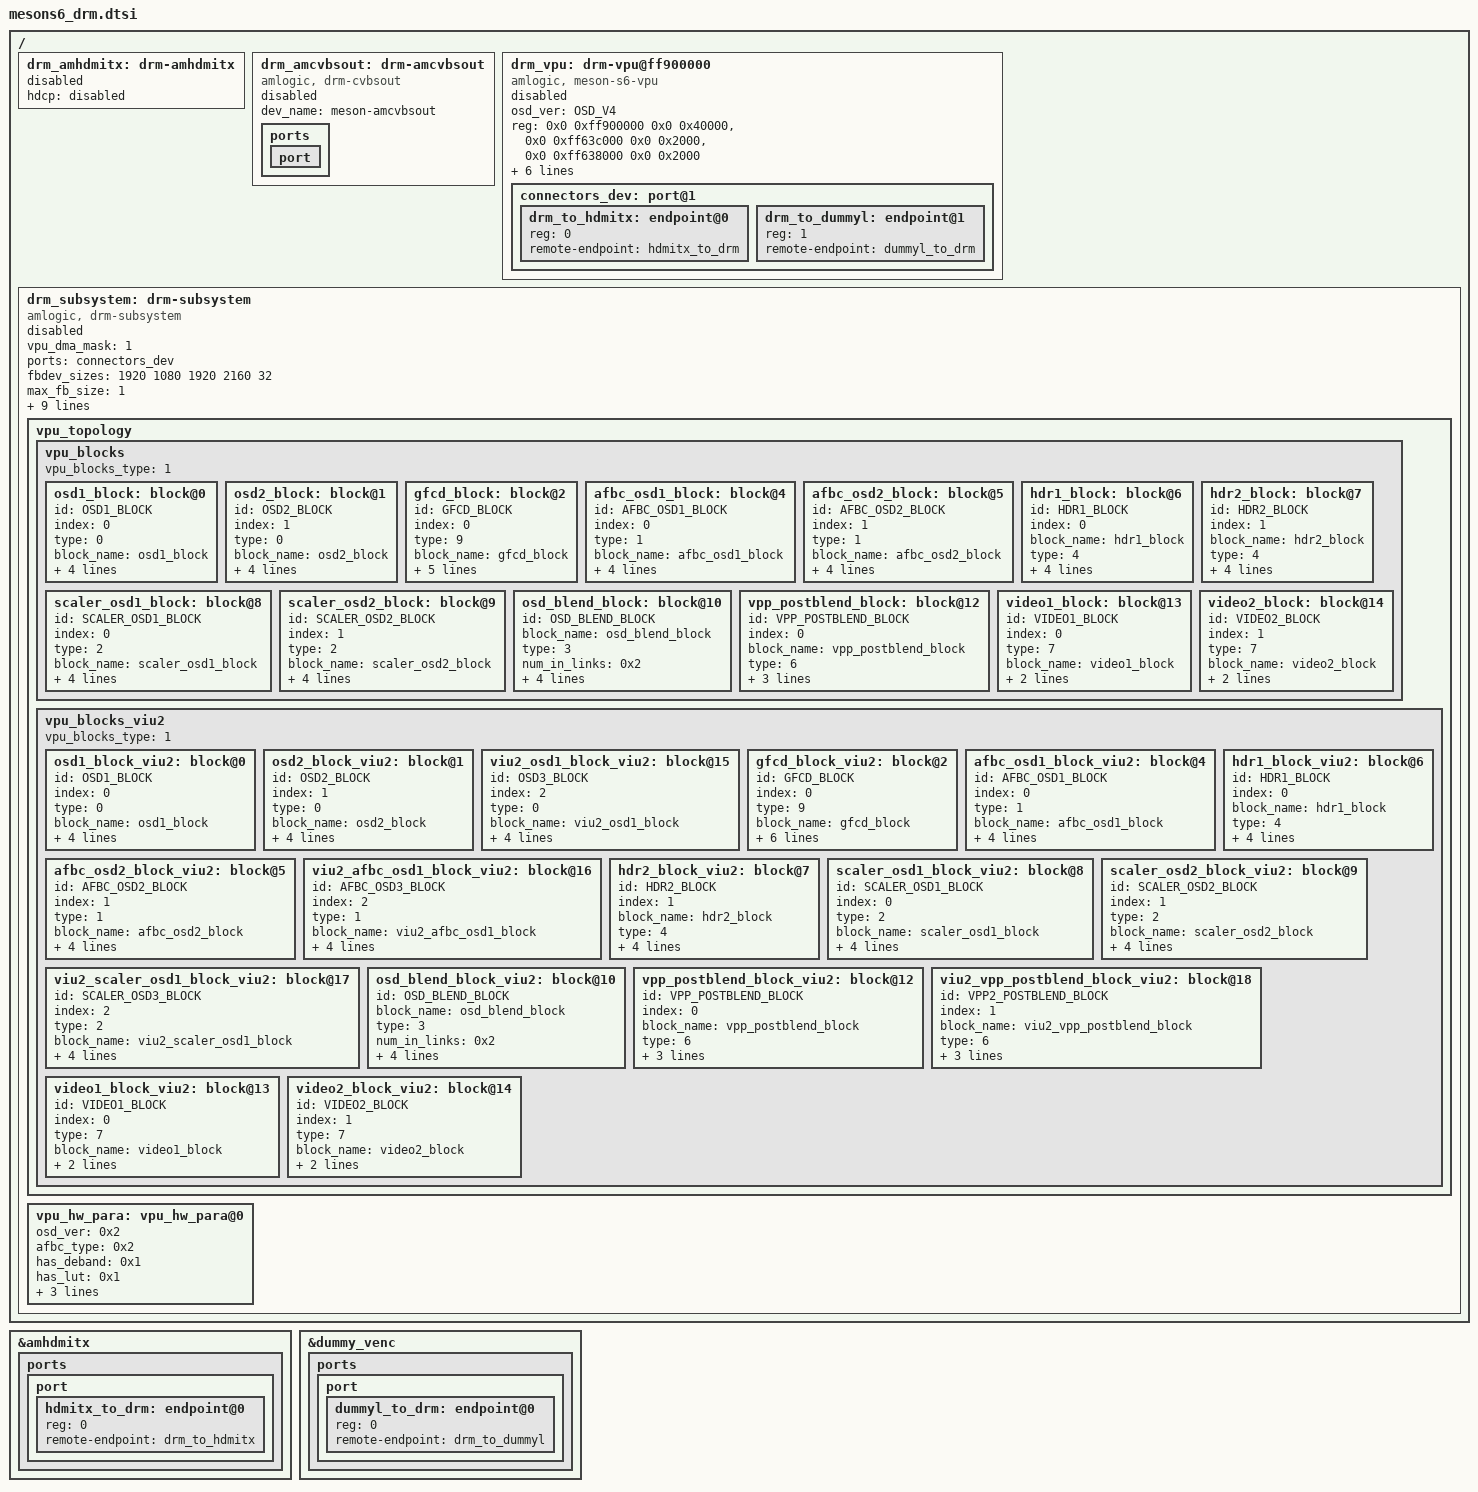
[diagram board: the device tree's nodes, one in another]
// SPDX-License-Identifier: (GPL-2.0+ OR MIT)
/*
 * Copyright (c) 2019 Amlogic, Inc. All rights reserved.
 */

#include <dt-bindings/display/meson-drm-ids.h>
#include "meson-s6.dtsi"

/ {
	drm_amhdmitx: drm-amhdmitx {
		status = "disabled";
		hdcp = "disabled";
	};

	drm_amcvbsout: drm-amcvbsout {
		status = "disabled";
		compatible = "amlogic, drm-cvbsout";
		dev_name = "meson-amcvbsout";
		ports {
			port {
				#address-cells = <1>;
				#size-cells = <0>;
			};
		};
	};

	drm_vpu: drm-vpu@ff900000  {
		status = "disabled";
		compatible = "amlogic, meson-s6-vpu";
		osd_ver = /bits/ 8 <OSD_V4>;
		reg = <0x0 0xff900000 0x0 0x40000>,
			  <0x0 0xff63c000 0x0 0x2000>,
			  <0x0 0xff638000 0x0 0x2000>;
		reg-names = "base", "hhi", "dmc";
		interrupts = <GIC_SPI 197 IRQ_TYPE_LEVEL_HIGH>,
				<GIC_SPI 194 IRQ_TYPE_LEVEL_HIGH>;
		interrupt-names = "viu-vsync", "viu2-vsync";
		dma-coherent;
		clocks = <&clkc CLKID_VPU_CLKC>;
		clock-names = "vpu_clkc";
		assigned-clocks = <&clkc CLKID_VPU_CLKC>;
		assigned-clock-rates = <200000000>;
		/*EXTERNAL port for driver outside of drm.*/
		connectors_dev: port@1 {
			#address-cells = <1>;
			#size-cells = <0>;
			drm_to_hdmitx: endpoint@0 {
				reg = <0>;
				remote-endpoint = <&hdmitx_to_drm>;
			};
			drm_to_dummyl: endpoint@1 {
				reg = <1>;
				remote-endpoint = <&dummyl_to_drm>;
			};
		};
	};

	drm_subsystem: drm-subsystem {
		status = "disabled";
		compatible = "amlogic, drm-subsystem";
		vpu_dma_mask = <1>; /* 0: <= 4G, 1: > 4G */
		ports = <&connectors_dev>;
		fbdev_sizes = <1920 1080 1920 2160 32>;
		max_fb_size = <1>; /** 0:1080p fb 1:4k fb */
		memory-region = <&logo_reserved>;
		primary_plane_index = <0>; /* primary plane index for crtcs */
		crtc_masks = <1 0 0>; /*for encoder: 0:hdmi 1:lcd 2:cvbs*/
		crtcmask_of_osd = <0 0 1>; /* indicate the crtc mask of osd plane */
		gamma_ctl = <0>; /*0:skip gamma init 1:gamma init*/
		pxp_mode = <0>;
		gfcd_enable = /bits/ 8  <1>;
		afbc_aligned_size = <1>; /*0:fbdev alloc non-afbc memory 1:fbdev alloc afbc memory*/
		vpu_block_select = <&vpu_blocks>;

		vpu_topology: vpu_topology {
			vpu_blocks: vpu_blocks {
				/*0:scaler1 after osdblend, 1:scaler1 before osdblend*/
				vpu_blocks_type = <1>;
				osd1_block: block@0 {
					id = /bits/ 8 <OSD1_BLOCK>;
					index = /bits/ 8  <0>;
					type = /bits/ 8  <0>;
					block_name = "osd1_block";
					num_in_links = /bits/ 8  <0x0>;
					num_out_links = /bits/ 8  <0x1>;
					out_links = <0 &gfcd_block>;
					capability = /bits/ 64 <0x80000C9F>;
				};
				osd2_block: block@1 {
					id = /bits/ 8  <OSD2_BLOCK>;
					index = /bits/ 8  <1>;
					type = /bits/ 8  <0>;
					block_name = "osd2_block";
					num_in_links = /bits/ 8  <0x0>;
					num_out_links = /bits/ 8  <0x1>;
					out_links = <1 &gfcd_block>;
					capability = /bits/ 64 <0x80000C9F>;
				};
				gfcd_block: block@2 {
					id = /bits/ 8  <GFCD_BLOCK>;
					index = /bits/ 8  <0>;
					type = /bits/ 8  <9>;
					block_name = "gfcd_block";
					num_in_links = /bits/ 8  <0x2>;
					in_links = <0 &osd1_block>,
						<0 &osd2_block>;
					num_out_links = /bits/ 8  <0x2>;
					out_links = <0 &afbc_osd1_block>,
						<0 &afbc_osd2_block>;
				};
				afbc_osd1_block: block@4 {
					id = /bits/ 8  <AFBC_OSD1_BLOCK>;
					index = /bits/ 8  <0>;
					type = /bits/ 8  <1>;
					block_name = "afbc_osd1_block";
					num_in_links = /bits/ 8  <0x1>;
					in_links = <0 &gfcd_block>;
					num_out_links = /bits/ 8  <0x1>;
					out_links = <0 &hdr1_block>;
				};
				afbc_osd2_block: block@5 {
					id = /bits/ 8  <AFBC_OSD2_BLOCK>;
					index = /bits/ 8  <1>;
					type = /bits/ 8  <1>;
					block_name = "afbc_osd2_block";
					num_in_links = /bits/ 8  <0x1>;
					in_links = <1 &gfcd_block>;
					num_out_links = /bits/ 8  <0x1>;
					out_links = <0 &hdr2_block>;
				};
				hdr1_block: block@6 {
					id = /bits/ 8  <HDR1_BLOCK>;
					index = /bits/ 8  <0>;
					block_name = "hdr1_block";
					type = /bits/ 8  <4>;
					num_in_links = /bits/ 8  <0x1>;
					in_links = <0 &afbc_osd1_block>;
					num_out_links = /bits/ 8  <0x1>;
					out_links = <0 &scaler_osd1_block>;
				};
				hdr2_block: block@7 {
					id = /bits/ 8  <HDR2_BLOCK>;
					index = /bits/ 8  <1>;
					block_name = "hdr2_block";
					type = /bits/ 8  <4>;
					num_in_links = /bits/ 8  <0x1>;
					in_links = <0 &afbc_osd2_block>;
					num_out_links = /bits/ 8  <0x1>;
					out_links = <0 &scaler_osd2_block>;
				};
				scaler_osd1_block: block@8 {
					id = /bits/ 8  <SCALER_OSD1_BLOCK>;
					index = /bits/ 8  <0>;
					type = /bits/ 8  <2>;
					block_name = "scaler_osd1_block";
					num_in_links = /bits/ 8  <0x1>;
					in_links = <0 &hdr1_block>;
					num_out_links = /bits/ 8  <0x1>;
					out_links = <0 &osd_blend_block>;
				};
				scaler_osd2_block: block@9 {
					id = /bits/ 8  <SCALER_OSD2_BLOCK>;
					index = /bits/ 8  <1>;
					type = /bits/ 8  <2>;
					block_name = "scaler_osd2_block";
					num_in_links = /bits/ 8  <0x1>;
					in_links = <0 &hdr2_block>;
					num_out_links = /bits/ 8  <0x1>;
					out_links = <2 &osd_blend_block>;
				};
				osd_blend_block: block@10 {
					id = /bits/ 8  <OSD_BLEND_BLOCK>;
					block_name = "osd_blend_block";
					type = /bits/ 8  <3>;
					num_in_links = /bits/ 8  <0x2>;
					in_links = <0 &scaler_osd1_block>,
						<0 &scaler_osd2_block>;
					num_out_links = /bits/ 8  <0x1>;
					out_links = <0 &vpp_postblend_block>;
				};
				vpp_postblend_block: block@12 {
					id = /bits/ 8  <VPP_POSTBLEND_BLOCK>;
					index = /bits/ 8  <0>;
					block_name = "vpp_postblend_block";
					type = /bits/ 8  <6>;
					num_in_links = /bits/ 8  <0x1>;
					in_links = <0 &osd_blend_block>;
					num_out_links = <0x0>;
				};
				video1_block: block@13 {
					id = /bits/ 8 <VIDEO1_BLOCK>;
					index = /bits/ 8  <0>;
					type = /bits/ 8  <7>;
					block_name = "video1_block";
					num_in_links = /bits/ 8  <0x0>;
					num_out_links = /bits/ 8  <0x0>;
				};
				video2_block: block@14 {
					id = /bits/ 8 <VIDEO2_BLOCK>;
					index = /bits/ 8  <1>;
					type = /bits/ 8  <7>;
					block_name = "video2_block";
					num_in_links = /bits/ 8  <0x0>;
					num_out_links = /bits/ 8  <0x0>;
				};
			};
			vpu_blocks_viu2: vpu_blocks_viu2 {
				/*0:scaler1 after osdblend, 1:scaler1 before osdblend*/
				vpu_blocks_type = <1>;
				osd1_block_viu2: block@0 {
					id = /bits/ 8 <OSD1_BLOCK>;
					index = /bits/ 8  <0>;
					type = /bits/ 8  <0>;
					block_name = "osd1_block";
					num_in_links = /bits/ 8  <0x0>;
					num_out_links = /bits/ 8  <0x1>;
					out_links = <0 &gfcd_block_viu2>;
					capability = /bits/ 64 <0x80000C9F>;
				};
				osd2_block_viu2: block@1 {
					id = /bits/ 8  <OSD2_BLOCK>;
					index = /bits/ 8  <1>;
					type = /bits/ 8  <0>;
					block_name = "osd2_block";
					num_in_links = /bits/ 8  <0x0>;
					num_out_links = /bits/ 8  <0x1>;
					out_links = <1 &gfcd_block_viu2>;
					capability = /bits/ 64 <0x80000C9F>;
				};
				viu2_osd1_block_viu2: block@15 {
					id = /bits/ 8  <OSD3_BLOCK>;
					index = /bits/ 8  <2>;
					type = /bits/ 8  <0>;
					block_name = "viu2_osd1_block";
					num_in_links = /bits/ 8  <0x0>;
					num_out_links = /bits/ 8  <0x1>;
					out_links = <0 &viu2_afbc_osd1_block_viu2>;
					capability = /bits/ 64 <0x80000003>;
				};
				gfcd_block_viu2: block@2 {
					id = /bits/ 8  <GFCD_BLOCK>;
					index = /bits/ 8  <0>;
					type = /bits/ 8  <9>;
					block_name = "gfcd_block";
					num_in_links = /bits/ 8  <0x2>;
					in_links = <0 &osd1_block_viu2>,
						<0 &osd2_block_viu2>;
					num_out_links = /bits/ 8  <0x2>;
					out_links = <0 &afbc_osd1_block_viu2>,
						<0 &afbc_osd2_block_viu2>;
				};
				afbc_osd1_block_viu2: block@4 {
					id = /bits/ 8  <AFBC_OSD1_BLOCK>;
					index = /bits/ 8  <0>;
					type = /bits/ 8  <1>;
					block_name = "afbc_osd1_block";
					num_in_links = /bits/ 8  <0x1>;
					in_links = <0 &gfcd_block_viu2>;
					num_out_links = /bits/ 8  <0x1>;
					out_links = <0 &hdr1_block_viu2>;
				};
				afbc_osd2_block_viu2: block@5 {
					id = /bits/ 8  <AFBC_OSD2_BLOCK>;
					index = /bits/ 8  <1>;
					type = /bits/ 8  <1>;
					block_name = "afbc_osd2_block";
					num_in_links = /bits/ 8  <0x1>;
					in_links = <1 &gfcd_block_viu2>;
					num_out_links = /bits/ 8  <0x1>;
					out_links = <0 &hdr2_block_viu2>;
				};
				viu2_afbc_osd1_block_viu2: block@16 {
					id = /bits/ 8  <AFBC_OSD3_BLOCK>;
					index = /bits/ 8  <2>;
					type = /bits/ 8  <1>;
					block_name = "viu2_afbc_osd1_block";
					num_in_links = /bits/ 8  <0x1>;
					in_links = <0 &viu2_osd1_block_viu2>;
					num_out_links = /bits/ 8  <0x1>;
					out_links = <0 &viu2_scaler_osd1_block_viu2>;
				};
				hdr1_block_viu2: block@6 {
					id = /bits/ 8  <HDR1_BLOCK>;
					index = /bits/ 8  <0>;
					block_name = "hdr1_block";
					type = /bits/ 8  <4>;
					num_in_links = /bits/ 8  <0x1>;
					in_links = <0 &afbc_osd1_block_viu2>;
					num_out_links = /bits/ 8  <0x1>;
					out_links = <0 &scaler_osd1_block_viu2>;
				};
				hdr2_block_viu2: block@7 {
					id = /bits/ 8  <HDR2_BLOCK>;
					index = /bits/ 8  <1>;
					block_name = "hdr2_block";
					type = /bits/ 8  <4>;
					num_in_links = /bits/ 8  <0x1>;
					in_links = <0 &afbc_osd2_block_viu2>;
					num_out_links = /bits/ 8  <0x1>;
					out_links = <0 &scaler_osd2_block_viu2>;
				};
				scaler_osd1_block_viu2: block@8 {
					id = /bits/ 8  <SCALER_OSD1_BLOCK>;
					index = /bits/ 8  <0>;
					type = /bits/ 8  <2>;
					block_name = "scaler_osd1_block";
					num_in_links = /bits/ 8  <0x1>;
					in_links = <0 &hdr1_block_viu2>;
					num_out_links = /bits/ 8  <0x1>;
					out_links = <0 &osd_blend_block_viu2>;
				};
				scaler_osd2_block_viu2: block@9 {
					id = /bits/ 8  <SCALER_OSD2_BLOCK>;
					index = /bits/ 8  <1>;
					type = /bits/ 8  <2>;
					block_name = "scaler_osd2_block";
					num_in_links = /bits/ 8  <0x1>;
					in_links = <0 &hdr2_block_viu2>;
					num_out_links = /bits/ 8  <0x1>;
					out_links = <2 &osd_blend_block_viu2>;
				};
				viu2_scaler_osd1_block_viu2: block@17 {
					id = /bits/ 8  <SCALER_OSD3_BLOCK>;
					index = /bits/ 8  <2>;
					type = /bits/ 8  <2>;
					block_name = "viu2_scaler_osd1_block";
					num_in_links = /bits/ 8  <0x1>;
					in_links = <0 &viu2_afbc_osd1_block_viu2>;
					num_out_links = /bits/ 8  <0x1>;
					out_links = <0 &viu2_vpp_postblend_block_viu2>;
				};
				osd_blend_block_viu2: block@10 {
					id = /bits/ 8  <OSD_BLEND_BLOCK>;
					block_name = "osd_blend_block";
					type = /bits/ 8  <3>;
					num_in_links = /bits/ 8  <0x2>;
					in_links = <0 &scaler_osd1_block_viu2>,
						<0 &scaler_osd2_block_viu2>;
					num_out_links = /bits/ 8  <0x1>;
					out_links = <0 &vpp_postblend_block_viu2>;
				};
				vpp_postblend_block_viu2: block@12 {
					id = /bits/ 8  <VPP_POSTBLEND_BLOCK>;
					index = /bits/ 8  <0>;
					block_name = "vpp_postblend_block";
					type = /bits/ 8  <6>;
					num_in_links = /bits/ 8  <0x1>;
					in_links = <0 &osd_blend_block_viu2>;
					num_out_links = <0x0>;
				};
				viu2_vpp_postblend_block_viu2: block@18 {
					id = /bits/ 8  <VPP2_POSTBLEND_BLOCK>;
					index = /bits/ 8  <1>;
					block_name = "viu2_vpp_postblend_block";
					type = /bits/ 8  <6>;
					num_in_links = /bits/ 8  <0x1>;
					in_links = <0 &viu2_scaler_osd1_block_viu2>;
					num_out_links = <0x0>;
				};
				video1_block_viu2: block@13 {
					id = /bits/ 8 <VIDEO1_BLOCK>;
					index = /bits/ 8  <0>;
					type = /bits/ 8  <7>;
					block_name = "video1_block";
					num_in_links = /bits/ 8  <0x0>;
					num_out_links = /bits/ 8  <0x0>;
				};
				video2_block_viu2: block@14 {
					id = /bits/ 8 <VIDEO2_BLOCK>;
					index = /bits/ 8  <1>;
					type = /bits/ 8  <7>;
					block_name = "video2_block";
					num_in_links = /bits/ 8  <0x0>;
					num_out_links = /bits/ 8  <0x0>;
				};
			};
		};

		vpu_hw_para: vpu_hw_para@0 {
			osd_ver = /bits/ 8 <0x2>;
			afbc_type = /bits/ 8 <0x2>;
			has_deband = /bits/ 8 <0x1>;
			has_lut = /bits/ 8 <0x1>;
			has_rdma = /bits/ 8 <0x1>;
			osd_fifo_len = /bits/ 8 <64>;
			vpp_fifo_len = /bits/ 32 <0xfff>;
		};
	};
};

&amhdmitx {
	ports {
		port {
			#address-cells = <1>;
			#size-cells = <0>;
			hdmitx_to_drm: endpoint@0 {
				reg = <0>;
				remote-endpoint = <&drm_to_hdmitx>;
			};
		};
	};
};

&dummy_venc {
	ports {
		port {
			#address-cells = <1>;
			#size-cells = <0>;
			dummyl_to_drm: endpoint@0 {
				reg = <0>;
				remote-endpoint = <&drm_to_dummyl>;
			};
		};
	};
};
